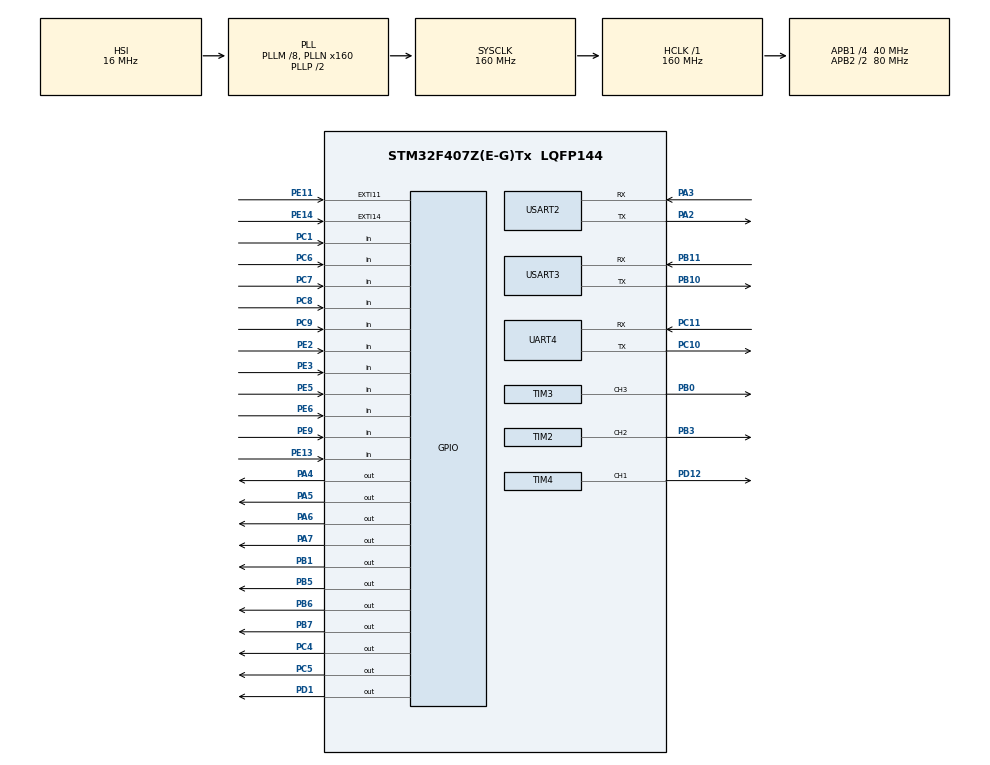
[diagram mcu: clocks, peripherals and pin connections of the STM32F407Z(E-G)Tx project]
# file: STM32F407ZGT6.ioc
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Mcu.Family=STM32F4
Mcu.Name=STM32F407Z(E-G)Tx
Mcu.Package=LQFP144
NVIC.EXTI15_10_IRQn=true\:0\:0\:false\:false\:true\:true\:true\:true
NVIC.PriorityGroup=NVIC_PRIORITYGROUP_4
NVIC.TIM1_UP_TIM10_IRQn=true\:0\:0\:false\:false\:true\:true\:true\:true
NVIC.UART4_IRQn=true\:0\:0\:false\:false\:true\:true\:true\:true
NVIC.USART2_IRQn=true\:0\:0\:false\:false\:true\:true\:true\:true
NVIC.USART3_IRQn=true\:0\:0\:false\:false\:true\:true\:true\:true
PA2.Mode=Asynchronous
PA2.Signal=USART2_TX
PA3.Mode=Asynchronous
PA3.Signal=USART2_RX
PA4.Signal=GPIO_Output
PA5.Signal=GPIO_Output
PA6.Signal=GPIO_Output
PA7.Signal=GPIO_Output
PB0.Signal=S_TIM3_CH3
PB1.Signal=GPIO_Output
PB10.Mode=Asynchronous
PB10.Signal=USART3_TX
PB11.Mode=Asynchronous
PB11.Signal=USART3_RX
PB3.Signal=S_TIM2_CH2
PB5.Signal=GPIO_Output
PB6.GPIO_ModeDefaultOutputPP=GPIO_MODE_OUTPUT_PP
PB6.Signal=GPIO_Output
PB7.GPIO_ModeDefaultOutputPP=GPIO_MODE_OUTPUT_OD
PB7.GPIO_PuPd=GPIO_NOPULL
PB7.Signal=GPIO_Output
PC1.Signal=GPIO_Input
PC10.Mode=Asynchronous
PC10.Signal=UART4_TX
PC11.Mode=Asynchronous
PC11.Signal=UART4_RX
PC4.Signal=GPIO_Output
PC5.Signal=GPIO_Output
PC6.Signal=GPIO_Input
PC7.Signal=GPIO_Input
PC8.Signal=GPIO_Input
PC9.Signal=GPIO_Input
PD1.Signal=GPIO_Output
PD12.Signal=S_TIM4_CH1
PE11.GPIO_PuPd=GPIO_PULLUP
PE11.Signal=GPXTI11
PE13.GPIO_PuPd=GPIO_PULLUP
PE13.Signal=GPIO_Input
PE14.GPIO_PuPd=GPIO_PULLUP
PE14.Signal=GPXTI14
PE2.Signal=GPIO_Input
PE3.Signal=GPIO_Input
PE5.Signal=GPIO_Input
PE6.Signal=GPIO_Input
PE9.GPIO_PuPd=GPIO_PULLUP
PE9.Signal=GPIO_Input
PH0-OSC_IN.Mode=HSE-External-Oscillator
PH0-OSC_IN.Signal=RCC_OSC_IN
PH1-OSC_OUT.Mode=HSE-External-Oscillator
PH1-OSC_OUT.Signal=RCC_OSC_OUT
ProjectManager.HeapSize=0x200
ProjectManager.StackSize=0x400
ProjectManager.TargetToolchain=MDK-ARM V5.32
RCC.48MHZClocksFreq_Value=80000000
RCC.AHBFreq_Value=160000000
RCC.APB1CLKDivider=RCC_HCLK_DIV4
RCC.APB1Freq_Value=40000000
RCC.APB1TimFreq_Value=80000000
RCC.APB2CLKDivider=RCC_HCLK_DIV2
RCC.APB2Freq_Value=80000000
RCC.APB2TimFreq_Value=160000000
RCC.CortexFreq_Value=160000000
RCC.HCLKFreq_Value=160000000
RCC.HSE_VALUE=25000000
RCC.HSI_VALUE=16000000
RCC.LSE_VALUE=32768
RCC.PLLM=8
RCC.PLLN=160
RCC.SYSCLKFreq_VALUE=160000000
RCC.SYSCLKSource=RCC_SYSCLKSOURCE_PLLCLK
RCC.VCOOutputFreq_Value=320000000
SH.S_TIM2_CH2.0=TIM2_CH2,PWM Generation2 CH2
SH.S_TIM3_CH3.0=TIM3_CH3,PWM Generation3 CH3
SH.S_TIM4_CH1.0=TIM4_CH1,PWM Generation1 CH1
TIM10.Period=9
TIM10.Prescaler=16799
TIM2.Channel-PWM\ Generation2\ CH2=TIM_CHANNEL_2
TIM2.Period=999
TIM2.Prescaler=11
TIM3.Channel-PWM\ Generation3\ CH3=TIM_CHANNEL_3
TIM3.Period=999
TIM3.Prescaler=11
TIM4.Channel-PWM\ Generation1\ CH1=TIM_CHANNEL_1
TIM4.Period=999
TIM4.Prescaler=335
UART4.VirtualMode=Asynchronous
USART2.VirtualMode=VM_ASYNC
USART3.VirtualMode=VM_ASYNC
VP_TIM10_VS_ClockSourceINT.Mode=Enable_Timer
board=custom

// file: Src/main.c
/* USER CODE BEGIN Header */
/**
  ******************************************************************************
  * @file           : main.c
  * @brief          : Main program body
  ******************************************************************************
  * @attention
  *
  * Copyright (c) 2022 STMicroelectronics.
  * All rights reserved.
  *
  * This software is licensed under terms that can be found in the LICENSE file
  * in the root directory of this software component.
  * If no LICENSE file comes with this software, it is provided AS-IS.
  *
  ******************************************************************************
  */
/* USER CODE END Header */
#include "main.h"
#include "tim.h"
#include "usart.h"
#include "gpio.h"
#include "SEEKFREE_MPU6050.h"
#include "SEEKFREE_18TFT.h"
#include "balance.h"
#include "menu.h"

void SystemClock_Config(void);

	key key_v;
int main(void)
{

  /* MCU Configuration--------------------------------------------------------*/

  /* Reset of all peripherals, Initializes the Flash interface and the Systick. */
  HAL_Init();

  /* Configure the system clock */
  SystemClock_Config();

  /* Initialize all configured peripherals */
  MX_GPIO_Init();
  MX_USART2_UART_Init();
  MX_TIM2_Init();
  MX_TIM3_Init();
  MX_TIM4_Init();
  MX_UART4_Init();
  MX_USART3_UART_Init();
  MX_TIM10_Init();
  /* USER CODE BEGIN 2 */
	//lcd_init();
	//lcd_showint8(0,0,0);

	HAL_GPIO_WritePin(GPIOB,GPIO_PIN_6,GPIO_PIN_SET);
	HAL_GPIO_WritePin(GPIOB,GPIO_PIN_7,GPIO_PIN_SET);
	HAL_GPIO_WritePin(GPIOE,GPIO_PIN_2,GPIO_PIN_SET);
	mpu6050_init();
	__HAL_TIM_CLEAR_IT(&htim10,TIM_IT_UPDATE);

	HAL_TIM_Base_Start_IT(&htim10);
  /* USER CODE END 2 */

  /* Infinite loop */
  /* USER CODE BEGIN WHILE */
  while (1)
  {
		key_v=key_check();
	if(key_v==key_enter)
	{
		HAL_UART_Transmit(&huart2,"h",1,50);
		HAL_UART_Transmit(&huart4,"a",1,50);
	}
//		Pitch_compute();
//		sprintf(ifString,"%.2f\n",pitch);
//		HAL_UART_Transmit(&huart2,ifString,sizeof(ifString),50);
//		HAL_Delay(10);
		//PWM2_duty(300);
    /* USER CODE END WHILE */

  }
}

void SystemClock_Config(void)
{
  RCC_OscInitTypeDef RCC_OscInitStruct = {0};
  RCC_ClkInitTypeDef RCC_ClkInitStruct = {0};

  /** Configure the main internal regulator output voltage
  */
  __HAL_RCC_PWR_CLK_ENABLE();
  __HAL_PWR_VOLTAGESCALING_CONFIG(PWR_REGULATOR_VOLTAGE_SCALE1);

  /** Initializes the RCC Oscillators according to the specified parameters
  * in the RCC_OscInitTypeDef structure.
  */
  RCC_OscInitStruct.OscillatorType = RCC_OSCILLATORTYPE_HSI;
  RCC_OscInitStruct.HSIState = RCC_HSI_ON;
  RCC_OscInitStruct.HSICalibrationValue = RCC_HSICALIBRATION_DEFAULT;
  RCC_OscInitStruct.PLL.PLLState = RCC_PLL_ON;
  RCC_OscInitStruct.PLL.PLLSource = RCC_PLLSOURCE_HSI;
  RCC_OscInitStruct.PLL.PLLM = 8;
  RCC_OscInitStruct.PLL.PLLN = 160;
  RCC_OscInitStruct.PLL.PLLP = RCC_PLLP_DIV2;
  RCC_OscInitStruct.PLL.PLLQ = 4;
  if (HAL_RCC_OscConfig(&RCC_OscInitStruct) != HAL_OK)
  {
    Error_Handler();
  }

  /** Initializes the CPU, AHB and APB buses clocks
  */
  RCC_ClkInitStruct.ClockType = RCC_CLOCKTYPE_HCLK|RCC_CLOCKTYPE_SYSCLK
                              |RCC_CLOCKTYPE_PCLK1|RCC_CLOCKTYPE_PCLK2;
  RCC_ClkInitStruct.SYSCLKSource = RCC_SYSCLKSOURCE_PLLCLK;
  RCC_ClkInitStruct.AHBCLKDivider = RCC_SYSCLK_DIV1;
  RCC_ClkInitStruct.APB1CLKDivider = RCC_HCLK_DIV4;
  RCC_ClkInitStruct.APB2CLKDivider = RCC_HCLK_DIV2;

  if (HAL_RCC_ClockConfig(&RCC_ClkInitStruct, FLASH_LATENCY_5) != HAL_OK)
  {
    Error_Handler();
  }
}

void Error_Handler(void)
{
  __disable_irq();
  while (1)
  {
  }
}
